# H3 register map
Vendor: Allwinner; Series: H3; File version: 0.1
CPU: 0, little endian, MPU, no FPU, 0 interrupt priority bits
Registers are 32-bit, read-write, reset 0x0 unless marked. A register's access mark holds for its fields unless they carry their own. Offsets are from the block's base; [hi:lo] are bit positions; {n}, {i} and the like mark numbered series.

## RTC
Base 0x01F00000
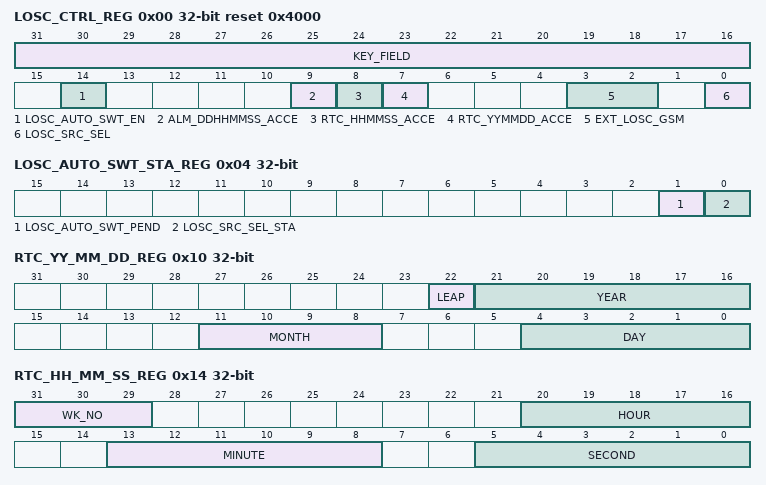
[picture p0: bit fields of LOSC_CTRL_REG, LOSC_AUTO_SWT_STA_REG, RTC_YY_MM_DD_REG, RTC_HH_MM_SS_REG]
0x00 LOSC_CTRL_REG reset 0x4000 — Low Oscillator Control Register
  [31:16] KEY_FIELD wo — Key Field. This field should be filled with 0x16AA, and then the bit 0 can be written with the new value.
  [14] LOSC_AUTO_SWT_EN — LOSC auto switch enable. 0: Disable, 1: Enable.
    0=Disable, 1: Enable
  [9] ALM_DDHHMMSS_ACCE — ALARM DD-HH-MM-SS access. After writing the ALARM DD-HH-MM-SS register, this bit is set and it will be cleared until the real writing operation is finished.
  [8] RTC_HHMMSS_ACCE — RTC HH-MM-SS access. After writing the RTC HH-MM-SS register, this bit is set and it will be cleared until the real writing operation is finished. After writing the RTC YY-MM-DD register, the YY-MM-DD register will be refreshed for at most one second.
  [7] RTC_YYMMDD_ACCE — RTC YY-MM-DD access. After writing the RTC YY-MM-DD register, this bit is set and it will be cleared until the real writing operation is finished. After writing the RTC YY-MM-DD register, the YY-MM-DD register will be refreshed for at most one second.
  [3:2] EXT_LOSC_GSM — External 32768Hz Crystal GSM. 00 low 01 10 11 high
  [0] LOSC_SRC_SEL — LOSC Clock source Select. `N` is the value of Internal OSC Clock Prescalar register. 0: InternalOSC /32/ N, 1: External 32.768KHz OSC. (InternalOSC=16MHz)
    0=InternalOSC /32/ N, 1: External 32.768KHz OSC. (InternalOSC=16MHz)
0x04 LOSC_AUTO_SWT_STA_REG — LOSC Auto Switch Status Register
  [1] LOSC_AUTO_SWT_PEND — LOSC auto switch pending. 0: No effect 1: Auto switches pending Set 1 to this bit will clear it.
    0=No_effect; 1=Auto switches pending Set 1 to this bit will clear it
  [0] LOSC_SRC_SEL_STA ro — Checking LOSC Clock Source Status. `N` is the value of Internal OSC Clock Prescalar register. 0: InternalOSC /32/ N 1: External 32.768KHz OSC (InternalOSC=16MHz)
    0=InternalOSC /32/ N; 1=External 32.768KHz OSC (InternalOSC=16MHz)
0x08 INTOSC_CLK_PRESCAL_REG reset 0xF — Internal OSC Clock Prescalar Register
  [15:0] INTOSC_CLK_PRESCAL — Internal OSC Clock Prescalar value N. 0x000: 1 0x001: 2 0x002: 3 ...... 0x1F: 32
    0=_1; 1=_2; 2=_3; 31=_32
0x10 RTC_YY_MM_DD_REG (reset mask 0x400000) — RTC Year-Month-Day Register
  [22] LEAP — Leap Year. 0: not, 1: Leap year. This bit can not set by hardware. It should be set or clear by software.
    0=not, 1: Leap year. This bit can not set by hardware. It should be set or clear by software.
  [21:16] YEAR — Year. Range from 0~63.
  [11:8] MONTH — Month. Range from 1~12.
  [4:0] DAY — Day. Range from 1~31.
0x14 RTC_HH_MM_SS_REG (reset mask 0xE0000000) — RTC Hour-Minute-Second Register
  [31:29] WK_NO — Week number. 000: Monday 001: Tuesday 010: Wednesday 011: Thursday 100: Friday 101: Saturday 110: Sunday 111: /
    0=Monday; 1=Tuesday; 2=Wednesday; 3=Thursday; 4=Friday; 5=Saturday; 6=Sunday
  [20:16] HOUR — Range from 0~23
  [13:8] MINUTE — Range from 0~59
  [5:0] SECOND — Range from 0~59
0x20 ALARM0_COUNTER_REG — Alarm 0 Counter Register
  [31:0] ALARM0_COUNTER — Alarm 0 Counter is Based on Second.
0x24 ALARM0_CUR_VLU_REG reset not defined — Alarm 0 Counter Current Value Register
  [31:0] ALARM0_CUR_VLU ro — Check Alarm 0 Counter Current Values.
0x28 ALARM0_ENABLE_REG — Alarm 0 Enable Register
  [0] ALM_0_EN — Alarm 0 Enable. If this bit is set to `1`, the Alarm 0 Counter register`s valid bits will down count to zero, and the alarm pending bit will be set to `1`. 0: Disable 1: Enable
    0=Disable; 1=Enable
0x2C ALARM0_IRQ_EN — Alarm 0 IRQ Enable Register
  [0] ALARM0_IRQ_EN — Alarm 0 IRQ Enable. 0: Disable 1: Enable
    0=Disable; 1=Enable
0x30 ALARM0_IRQ_STA_REG — Alarm 0 IRQ Status Register
  [0] ALARM0_IRQ_PEND — Alarm 0 IRQ Pending bit. 0: No effect 1: Pending, alarm 0 counter value is reached If alarm 0 irq enable is set to 1, the pending bit will be sent to the interrupt controller.
    0=No_effect; 1=Pending, alarm 0 counter value is reached If alarm 0 irq enable is set to 1, the pending bit will be sent to the interrupt controller
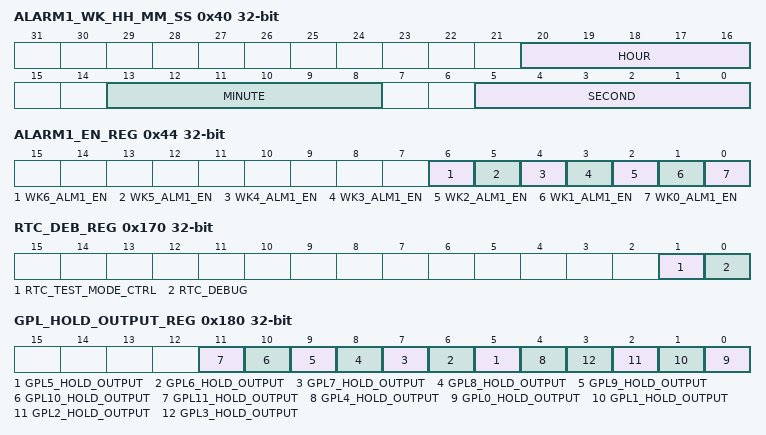
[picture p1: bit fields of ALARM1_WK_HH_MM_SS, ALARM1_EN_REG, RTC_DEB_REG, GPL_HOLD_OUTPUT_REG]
0x40 ALARM1_WK_HH_MM_SS reset not defined
  [20:16] HOUR — Range from 0~23.
  [13:8] MINUTE — Range from 0~59.
  [5:0] SECOND — Range from 0~59.
0x44 ALARM1_EN_REG
  [6] WK6_ALM1_EN — Week 6 (Sunday) Alarm 1 Enable. 0: Disable 1: Enable If this bit is set to `1`, only when the Alarm 1 Week HH-MM-SS register valid bits is equal to RTC HH-MM-SS register and the register RTC HH-MM-SS bit [31:29] is 6, the week 6 alarm irq pending bit will be set to `1`.
    0=Disable; 1=Enable If this bit is set to `1`, only when the Alarm 1 Week HH-MM-SS register valid bits is equal to RTC HH-MM-SS register and the register RTC HH-MM-SS bit [31:29] is 6, the week 6 alarm irq pending bit will be set to `1`
  [5] WK5_ALM1_EN — Week 5 (Saturday) Alarm 1 Enable. 0: Disable 1: Enable If this bit is set to `1`, only when the Alarm 1 Week HH-MM-SS register valid bits is equal to RTC HH-MM-SS register and the register RTC HH-MM-SS bit [31:29] is 5, the week 5 alarm irq pending bit will be set to `1`.
    0=Disable; 1=Enable If this bit is set to `1`, only when the Alarm 1 Week HH-MM-SS register valid bits is equal to RTC HH-MM-SS register and the register RTC HH-MM-SS bit [31:29] is 5, the week 5 alarm irq pending bit will be set to `1`
  [4] WK4_ALM1_EN — Week 4 (Friday) Alarm 1 Enable. 0: Disable 1: Enable If this bit is set to `1`, only when the Alarm 1 Week HH-MM-SS register valid bits is equal to RTC HH-MM-SS register and the register RTC HH-MM-SS bit [31:29] is 4, the week 4 alarm irq pending bit will be set to `1`.
    0=Disable; 1=Enable If this bit is set to `1`, only when the Alarm 1 Week HH-MM-SS register valid bits is equal to RTC HH-MM-SS register and the register RTC HH-MM-SS bit [31:29] is 4, the week 4 alarm irq pending bit will be set to `1`
  [3] WK3_ALM1_EN — Week 3 (Thursday) Alarm 1 Enable. 0: Disable 1: Enable If this bit is set to `1`, only when the Alarm 1 Week HH-MM-SS register valid bits is equal to RTC HH-MM-SS register and the register RTC HH-MM-SS bit [31:29] is 3, the week 3 alarm irq pending bit will be set to `1`.
    0=Disable; 1=Enable If this bit is set to `1`, only when the Alarm 1 Week HH-MM-SS register valid bits is equal to RTC HH-MM-SS register and the register RTC HH-MM-SS bit [31:29] is 3, the week 3 alarm irq pending bit will be set to `1`
  [2] WK2_ALM1_EN — Week 2 (Wednesday) Alarm 1 Enable. 0: Disable 1: Enable If this bit is set to `1`, only when the Alarm 1 Week HH-MM-SS register valid bits is equal to RTC HH-MM-SS register and the register RTC HH-MM-SS bit [31:29] is 2, the week 2 alarm irq pending bit will be set to `1`.
    0=Disable; 1=Enable If this bit is set to `1`, only when the Alarm 1 Week HH-MM-SS register valid bits is equal to RTC HH-MM-SS register and the register RTC HH-MM-SS bit [31:29] is 2, the week 2 alarm irq pending bit will be set to `1`
  [1] WK1_ALM1_EN — Week 1 (Tuesday) Alarm 1 Enable. 0: Disable 1: Enable If this bit is set to `1`, only when the Alarm 1 Week HH-MM-SS register valid bits is equal to RTC HH-MM-SS register and the register RTC HH-MM-SS bit [31:29] is 1, the week 1 alarm irq pending bit will be set to `1`.
    0=Disable; 1=Enable If this bit is set to `1`, only when the Alarm 1 Week HH-MM-SS register valid bits is equal to RTC HH-MM-SS register and the register RTC HH-MM-SS bit [31:29] is 1, the week 1 alarm irq pending bit will be set to `1`
  [0] WK0_ALM1_EN — Week 0 (Monday) Alarm 1 Enable. 0: Disable 1: Enable If this bit is set to `1`, only when the Alarm 1 Week HH-MM-SS register valid bits is equal to RTC HH-MM-SS register and the register RTC HH-MM-SS bit [31:29] is 0, the week 0 alarm irq pending bit will be set to `1`.
    0=Disable; 1=Enable If this bit is set to `1`, only when the Alarm 1 Week HH-MM-SS register valid bits is equal to RTC HH-MM-SS register and the register RTC HH-MM-SS bit [31:29] is 0, the week 0 alarm irq pending bit will be set to `1`
0x48 ALARM1_IRQ_EN — Alarm 1 IRQ Enable Register
  [0] ALARM1_IRQ_EN — Alarm 1 IRQ Enable. 0: Disable 1: Enable
    0=Disable; 1=Enable
0x4C ALARM1_IRQ_STA_REG — Alarm 1 IRQ Status Register
  [0] ALARM1_WEEK_IRQ_PEND — Alarm 1 Week (0/1/2/3/4/5/6) IRQ Pending. 0: No effect 1: Pending, week counter value is reached If alarm 1 week irq enable is set to 1, the pending bit will be sent to the interrupt controller.
    0=No_effect; 1=Pending, week counter value is reached If alarm 1 week irq enable is set to 1, the pending bit will be sent to the interrupt controller
0x50 ALARM_CONFIG_REG — Alarm Config Register
  [0] ALARM_WAKEUP — Configuration of alarm wake up output. 0: Disable alarm wake up output 1: Enable alarm wake up output
    0=Disable alarm wake up output; 1=Enable alarm wake up output
0x60 LOSC_OUT_GATING_REG — LOSC output gating register
  [0] LOSC_OUT_GATING — Configuration of LOSC output, and no LOSC output by default. 0: Enable LOSC output gating 1: Disable LOSC output gating
    0=Enable LOSC output gating; 1=Disable LOSC output gating
{0x100+4i} GP_DATA_REGn[{i}] (i=0..7) — GP_DATA_REGn[{i}]
  [31:0] GP_DATA — Data [31:0].
0x170 RTC_DEB_REG — RTC Debug Register
  [1] RTC_TEST_MODE_CTRL — RTC TEST Mode Control bit.
  [0] RTC_DEBUG — RTC Simulation Control bit 0: No effect. 1: simulation mode
    0=No_effect; 1=simulation_mode
0x180 GPL_HOLD_OUTPUT_REG — GPL Hold Output Register
  [all] fields
    0=Hold_disable; 1=Hold_enable
  [n] GPL{n}_HOLD_OUTPUT (n=5..11) — Hold the output of GPIOL{n} when system`s power is changing. The output must be low level (0) or high level (1) or High-Z; any other outputs may not hold on. 0: Hold disable 1: Hold enable
  [4] GPL4_HOLD_OUTPUT — Hold the output of GPIOL4 when system`s power is changing. The outputs must be low level (0) or high level (1) or High-Z; any other output may not hold on. 0: Hold disable 1: Hold enable
  [n] GPL{n}_HOLD_OUTPUT (n=0..3) — Hold the output of GPIOL{n} when system`s power is changing. The output must be low level (0) or high level (1) or High-Z; any other outputs may not hold on. 0: Hold disable 1: Hold enable
0x190 VDD_RTC_REG reset 0x4 — VDD RTC Regulate Register
  [2:0] VDD_RTC_REGU — These bits are useful for regulating the RTC_VIO from 0.7v to 1.4v, and the regulation step is 0.1v. 000: 0.7v 001: 0.8v 010: 0.9v 011: 1.0v 100: 1.1v 101: 1.2v 110: 1.3v 111: 1.4v
    0=_0_point_7v (0.7v); 1=_0_point_8v (0.8v); 2=_0_point_9v (0.9v); 3=_1_point_0v (1.0v); 4=_1_point_1v (1.1v); 5=_1_point_2v (1.2v); 6=_1_point_3v (1.3v); 7=_1_point_4v (1.4v)
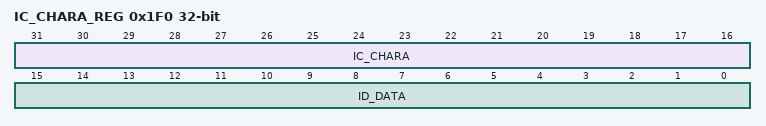
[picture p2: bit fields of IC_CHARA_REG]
0x1F0 IC_CHARA_REG — IC Characteristic Register
  [31:16] IC_CHARA — Key Field. Should be written at value 0x16AA. Writing any other value in this field aborts the write operation.
  [15:0] ID_DATA — Return 0x16aa only if the KEY_FIELD is set as 0x16aa when read those bits, otherwise return 0x0.
